# WE2_S_NS register map
Vendor: ARM Ltd.; Series: ARMv8.1-M Mainline; File version: 1.0
CPU: CM55 r1p1, little endian, MPU, FPU, double-precision FPU, DSP, VTOR, 3 interrupt priority bits
Registers are 32-bit, read-write, reset 0x0 unless marked. A register's access mark holds for its fields unless they carry their own. Offsets are from the block's base; [hi:lo] are bit positions; {n}, {i} and the like mark numbered series; 'fields as' and 'values as' point back to an identical list.

## SYS_CM — Cache maintenance operations
Base 0xE000EF50
Same registers: SYS_CM_NS 0xE002EF50
0x00 ICIALLU wo — Instruction Cache Invalidate All to PoU
  [31:0] Ignored — The value written to this field is ignored.
0x08 ICIMVAU — Instruction Cache line Invalidate by Address to PoU
  [31:0] Address — Writing to this field initiates the maintenance operation for the address that is written.
0x0C DCIMVAC — Data Cache line Invalidate by Address to PoC
  fields as ICIMVAU
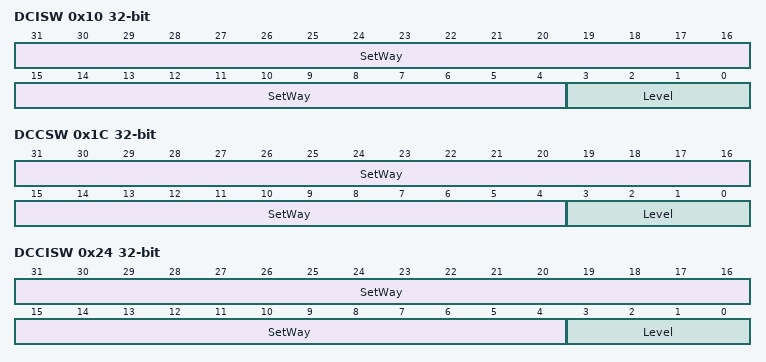
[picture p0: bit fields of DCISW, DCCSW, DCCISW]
0x10 DCISW — Data Cache line Invalidate by Set/Way
  [31:4] SetWay — Cache set/way.
  [3:0] Level — Cache level. This field is 0b000.
0x14 DCCMVAU — Data cache clean by address to the PoU
  fields as ICIMVAU
0x18 DCCMVAC — Data Cache Clean and Invalidate by Address to the PoC
  fields as ICIMVAU
0x1C DCCSW — Data Cache Clean line by Set/Way
  fields as DCISW
0x20 DCCIMVAC — Data Cache Clean and Invalidate by Address to the PoC
  fields as ICIMVAU
0x24 DCCISW — Data Cache Clean and Invalidate by Set/Way
  fields as DCISW
0x28 BPIALL — Branch Predictor Invalidate All
  [31:0] Ignored — The value written to this field is ignored.

## SYS_SAU — Security Attribution Unit (SAU) register
Base 0xE000EDD0
0x00 SAU_CTRL — SAU Control Register
0x04 SAU_TYPE ro
0x08 SAU_RNR — SAU Region Number Register
0x0C SAU_RBAR — SAU Region Base Address Register
0x10 SAU_RLAR — SAU Region Limit Address Register
0x14 SFSR — Secure Fault Status Register
0x18 SFAR — Secure Fault Address Register

## SYS_MPU — Memory Protection Unit (MPU) register
Base 0xE000ED90
Same registers: SYS_MPU_NS 0xE002ED90
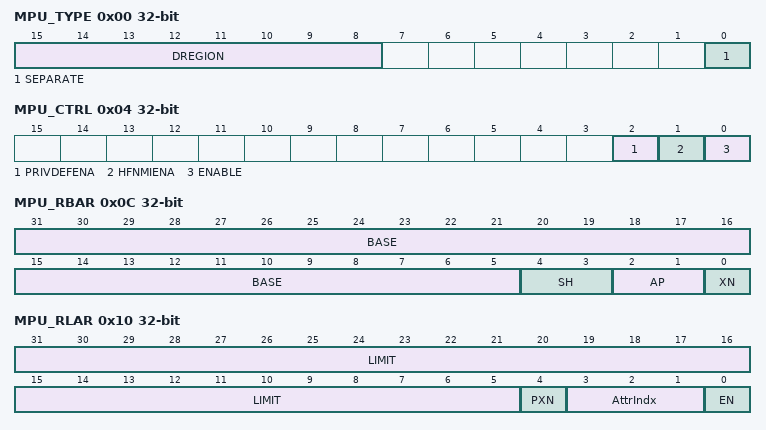
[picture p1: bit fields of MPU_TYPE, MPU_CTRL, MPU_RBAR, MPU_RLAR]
0x00 MPU_TYPE ro
  [15:8] DREGION — Data regions. Number of regions supported by the MPU. [0x00] Zero regions if your device does not include the MPU. [0x04] Four regions if your device includes the MPU. This value is implementation defined. [0x08] Eight regions if your device includes the MPU. This value is implementation defined. [0x0C] 12 regions if your device includes the MPU. This value is implementation defined. [0x10] 16 regions if your device includes the MPU. This value is implementation defined.
  [0] SEPARATE — Indicates support for unified or separate instructions and data address regions. Armv8-M only supports unified MPU regions. [0] Unified.
0x04 MPU_CTRL — MPU Control Register
  [2] PRIVDEFENA — Enables privileged software access to the default memory map. When the MPU is enabled: [0] Disables use of the default memory map. Any memory access to a location that is not covered by any enabled region causes a fault. [1] Enables use of the default memory map as a background region for privileged software accesses.
  [1] HFNMIENA — Enables the operation of MPU during HardFault and NMI handlers. When the MPU is enabled: [0] MPU is disabled during HardFault and NMI handlers, regardless of the value of the ENABLE bit. [1] The MPU is enabled during HardFault and NMI handlers.
  [0] ENABLE — Enables the MPU: [0] MPU is disabled. [1] MPU is enabled.
0x08 MPU_RNR — MPU Region Number Register
  [7:0] REGION — Regions. Indicates the memory region accessed by MPU_RBAR and PMU_RLAR. If no MPU region is implemented, this field is reserved. Writing a value corresponding to an unimplemented region is CONSTRAINED UNPREDICTABLE.
0x0C MPU_RBAR — MPU Region Base Address Register
  [31:5] BASE — Contains bits[31:5] of the lower inclusive limit of the selected MPU memory region. This value is zero extended to provide the base address to be checked against.
  [4:3] SH — Shareability. Defines the shareability domain of this region for Normal memory. [0b00] Non-shareable. [0b01] UNPREDICTABLE. [0b10] Outer shareable. [0b11] Inner Shareable.
  [2:1] AP — Access permissions. [0b00] Read/write by privileged code only. [0b01] Read/write by any privilege level. [0b10] Read-only by privileged code only. [0b11] Read-only by any privilege level.
  [0] XN — Execute Never. Defines whether code can be executed from this region. [0] Execution only permitted if read permitted. [1] Execution not permitted.
0x10 MPU_RLAR — MPU Region Limit Address Register
  [31:5] LIMIT — Limit address. Contains bits[31:5] of the upper inclusive limit of the selected MPU memory region. This value is postfixed with 0x1F to provide the limit address to be checked against.
  [4] PXN — Privileged execute never. Defines whether code can be executed from this privileged region. [0] Execution only permitted if read permitted. [1] Execution from a privileged mode is not permitted.
  [3:1] AttrIndx — Attribute index. Associates a set of attributes in the MPU_MAIR0 and MPU_MAIR1 fields.
  [0] EN — Enable. Region enable. The possible values of this bit are: [0] Region disabled. [1] Region enabled.
{0xC+8i} MPU_RBAR_A{i} (i=1..3) — MPU Region Base Address Register Alias {i}
{0x10+8i} MPU_RLAR_A{i} (i=1..3) — MPU Region Limit Address Register Alias {i}
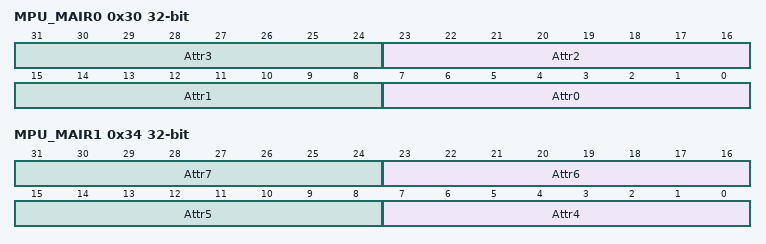
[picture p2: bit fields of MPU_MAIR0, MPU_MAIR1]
0x30 MPU_MAIR0 — MPU Memory Attribute Indirection Registers 0
  [8n+7:8n] Attr{n} (n=0..3)
0x34 MPU_MAIR1 — MPU Memory Attribute Indirection Registers 1
  [8n-25:8n-32] Attr{n} (n=4..7)
